# STM32WB35CCU6A register map
File version: 1.0
Registers are 32-bit, access not given, reset 0x0 unless marked. A register's access mark holds for its fields unless they carry their own. Offsets are from the block's base; [hi:lo] are bit positions; {n}, {i} and the like mark numbered series.

## VREFBUF
Base 0x40010030
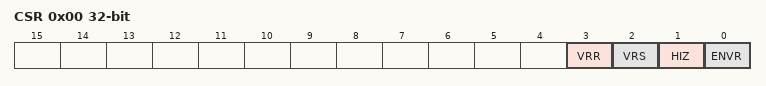
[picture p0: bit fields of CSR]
0x00 CSR
  [3] VRR, [2] VRS, [1] HIZ, [0] ENVR
0x04 CCR
  [5:0] TRIM

## COMP
Base 0x40010200
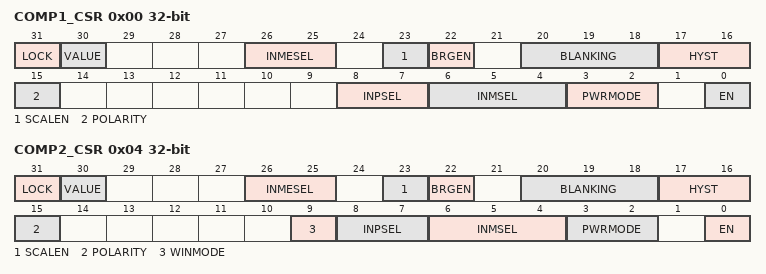
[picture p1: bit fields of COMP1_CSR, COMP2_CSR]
0x00 COMP1_CSR
  [31] LOCK, [30] VALUE, [26:25] INMESEL, [23] SCALEN, [22] BRGEN, [20:18] BLANKING, [17:16] HYST, [15] POLARITY, [8:7] INPSEL, [6:4] INMSEL, [3:2] PWRMODE, [0] EN
0x04 COMP2_CSR
  [31] LOCK, [30] VALUE, [26:25] INMESEL, [23] SCALEN, [22] BRGEN, [20:18] BLANKING, [17:16] HYST, [15] POLARITY, [9] WINMODE, [8:7] INPSEL, [6:4] INMSEL, [3:2] PWRMODE, [0] EN

## TIM1
Base 0x40012C00
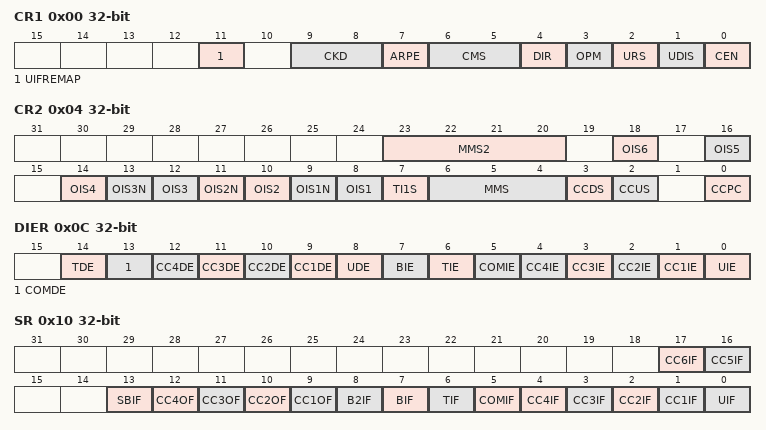
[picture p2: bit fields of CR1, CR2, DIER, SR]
0x00 CR1
  [11] UIFREMAP, [9:8] CKD, [7] ARPE, [6:5] CMS, [4] DIR, [3] OPM, [2] URS, [1] UDIS, [0] CEN
0x04 CR2
  [23:20] MMS2, [2n+6] OIS{n} (n=1..6), [13] OIS3N, [11] OIS2N, [9] OIS1N, [7] TI1S, [6:4] MMS, [3] CCDS, [2] CCUS, [0] CCPC
0x08 SMCR
  [15] ETP, [14] ECE, [13:12] ETPS, [11:8] ETF, [7] MSM, [21:4] TS, [3] OCCS, [16:0] SMS
0x0C DIER
  [14] TDE, [13] COMDE, [n+8] CC{n}DE (n=1..4), [8] UDE, [7] BIE, [6] TIE, [5] COMIE, [n] CC{n}IE (n=1..4), [0] UIE
0x10 SR
  [17] CC6IF, [16] CC5IF, [13] SBIF, [n+8] CC{n}OF (n=1..4), [8] B2IF, [7] BIF, [6] TIF, [5] COMIF, [n] CC{n}IF (n=1..4), [0] UIF
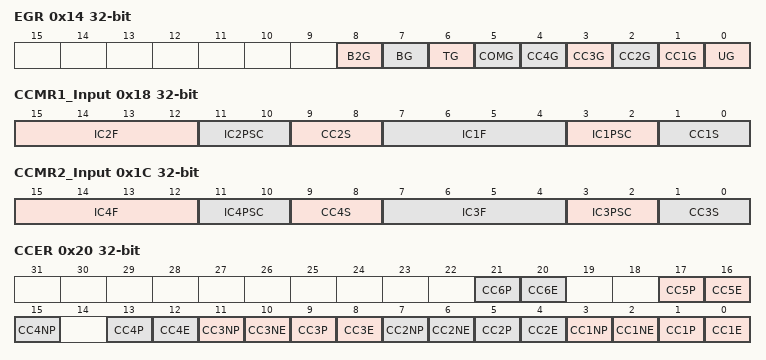
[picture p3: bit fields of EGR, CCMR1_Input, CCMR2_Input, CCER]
0x14 EGR
  [8] B2G, [7] BG, [6] TG, [5] COMG, [n] CC{n}G (n=1..4), [0] UG
0x18 CCMR1_Output
  [15] OC2CE, [24:12] OC2M, [11] OC2PE, [10] OC2FE, [9:8] CC2S, [7] OC1CE, [16:4] OC1M, [3] OC1PE, [2] OC1FE, [1:0] CC1S
0x18 CCMR1_Input
  [15:12] IC2F, [11:10] IC2PSC, [9:8] CC2S, [7:4] IC1F, [3:2] IC1PSC, [1:0] CC1S
0x1C CCMR2_Output
  [15] OC4CE, [24:12] OC4M, [11] OC4PE, [10] OC4FE, [9:8] CC4S, [7] OC3CE, [16:4] OC3M, [3] OC3PE, [2] OC3FE, [1:0] CC3S
0x1C CCMR2_Input
  [15:12] IC4F, [11:10] IC4PSC, [9:8] CC4S, [7:4] IC3F, [3:2] IC3PSC, [1:0] CC3S
0x20 CCER
  [4n-3] CC{n}P (n=1..6), [4n-4] CC{n}E (n=1..6), [4n-1] CC{n}NP (n=1..4), [10] CC3NE, [6] CC2NE, [2] CC1NE
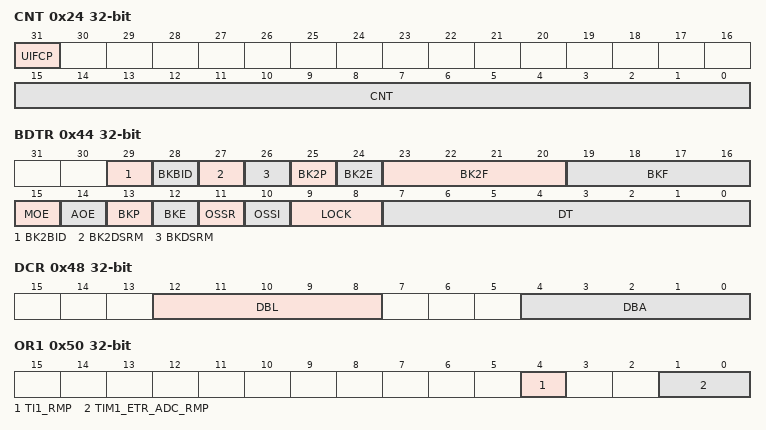
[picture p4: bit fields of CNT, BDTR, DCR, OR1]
0x24 CNT
  [31] UIFCP, [15:0] CNT
0x28 PSC
  [15:0] PSC
0x2C ARR
  [15:0] ARR
0x30 RCR
  [15:0] REP
{0x30+4i} CCR{i} (i=1..4)
  [15:0] CCR{i}
0x44 BDTR
  [29] BK2BID, [28] BKBID, [27] BK2DSRM, [26] BKDSRM, [25] BK2P, [24] BK2E, [23:20] BK2F, [19:16] BKF, [15] MOE, [14] AOE, [13] BKP, [12] BKE, [11] OSSR, [10] OSSI, [9:8] LOCK, [7:0] DT
0x48 DCR
  [12:8] DBL, [4:0] DBA
0x4C DMAR
  [31:0] DMAB
0x50 OR1
  [4] TI1_RMP, [1:0] TIM1_ETR_ADC_RMP
0x54 CCMR3_Output
  [15] OC6CE, [24:12] OC6M, [11] OC6PE, [10] OC6FE, [7] OC5CE, [16:4] OC5M, [3] OC5PE, [2] OC5FE
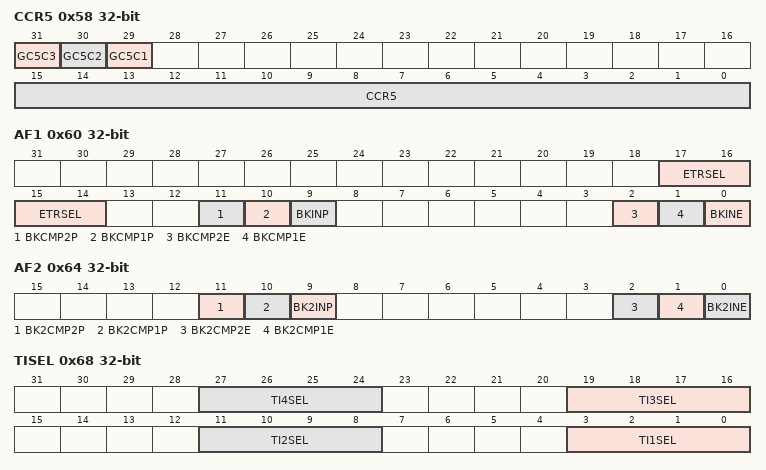
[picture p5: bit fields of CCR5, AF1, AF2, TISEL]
0x58 CCR5
  [31] GC5C3, [30] GC5C2, [29] GC5C1, [15:0] CCR5
0x5C CCR6
  [15:0] CCR6
0x60 AF1
  [17:14] ETRSEL, [11] BKCMP2P, [10] BKCMP1P, [9] BKINP, [2] BKCMP2E, [1] BKCMP1E, [0] BKINE
0x64 AF2
  [11] BK2CMP2P, [10] BK2CMP1P, [9] BK2INP, [2] BK2CMP2E, [1] BK2CMP1E, [0] BK2INE
0x68 TISEL
  [8n-5:8n-8] TI{n}SEL (n=1..4)

## USART1
Base 0x40013800
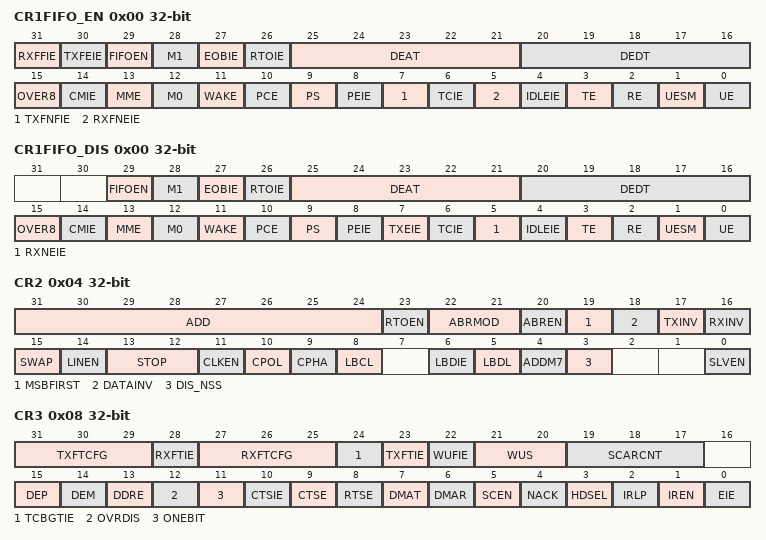
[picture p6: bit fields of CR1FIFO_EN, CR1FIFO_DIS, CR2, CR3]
0x00 CR1FIFO_EN
  [31] RXFFIE, [30] TXFEIE, [29] FIFOEN, [28] M1, [27] EOBIE, [26] RTOIE, [25:21] DEAT, [20:16] DEDT, [15] OVER8, [14] CMIE, [13] MME, [12] M0, [11] WAKE, [10] PCE, [9] PS, [8] PEIE, [7] TXFNFIE, [6] TCIE, [5] RXFNEIE, [4] IDLEIE, [3] TE, [2] RE, [1] UESM, [0] UE
0x00 CR1FIFO_DIS
  [29] FIFOEN, [28] M1, [27] EOBIE, [26] RTOIE, [25:21] DEAT, [20:16] DEDT, [15] OVER8, [14] CMIE, [13] MME, [12] M0, [11] WAKE, [10] PCE, [9] PS, [8] PEIE, [7] TXEIE, [6] TCIE, [5] RXNEIE, [4] IDLEIE, [3] TE, [2] RE, [1] UESM, [0] UE
0x04 CR2
  [31:24] ADD, [23] RTOEN, [22:21] ABRMOD, [20] ABREN, [19] MSBFIRST, [18] DATAINV, [17] TXINV, [16] RXINV, [15] SWAP, [14] LINEN, [13:12] STOP, [11] CLKEN, [10] CPOL, [9] CPHA, [8] LBCL, [6] LBDIE, [5] LBDL, [4] ADDM7, [3] DIS_NSS, [0] SLVEN
0x08 CR3
  [31:29] TXFTCFG, [28] RXFTIE, [27:25] RXFTCFG, [24] TCBGTIE, [23] TXFTIE, [22] WUFIE, [21:20] WUS, [19:17] SCARCNT, [15] DEP, [14] DEM, [13] DDRE, [12] OVRDIS, [11] ONEBIT, [10] CTSIE, [9] CTSE, [8] RTSE, [7] DMAT, [6] DMAR, [5] SCEN, [4] NACK, [3] HDSEL, [2] IRLP, [1] IREN, [0] EIE
0x0C BRR
  [15:0] BRR
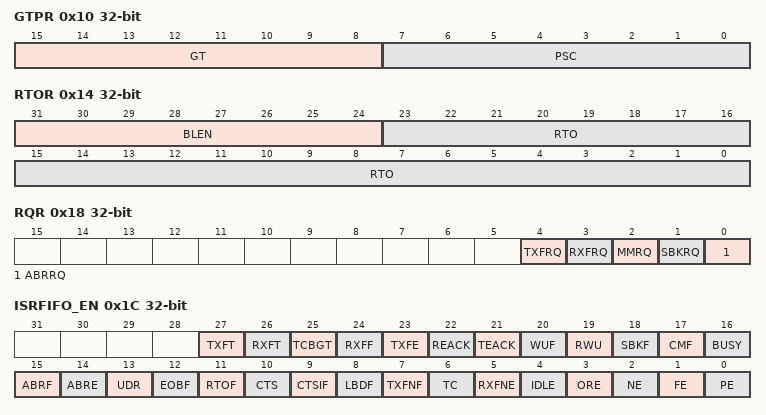
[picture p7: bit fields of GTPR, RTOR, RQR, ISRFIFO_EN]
0x10 GTPR
  [15:8] GT, [7:0] PSC
0x14 RTOR
  [31:24] BLEN, [23:0] RTO
0x18 RQR
  [4] TXFRQ, [3] RXFRQ, [2] MMRQ, [1] SBKRQ, [0] ABRRQ
0x1C ISRFIFO_EN
  [27] TXFT, [26] RXFT, [25] TCBGT, [24] RXFF, [23] TXFE, [22] REACK, [21] TEACK, [20] WUF, [19] RWU, [18] SBKF, [17] CMF, [16] BUSY, [15] ABRF, [14] ABRE, [13] UDR, [12] EOBF, [11] RTOF, [10] CTS, [9] CTSIF, [8] LBDF, [7] TXFNF, [6] TC, [5] RXFNE, [4] IDLE, [3] ORE, [2] NE, [1] FE, [0] PE
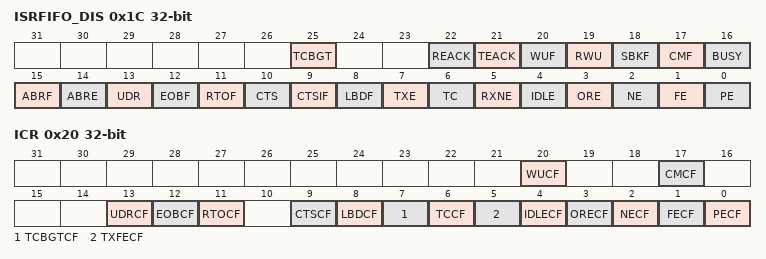
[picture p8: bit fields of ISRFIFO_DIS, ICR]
0x1C ISRFIFO_DIS
  [25] TCBGT, [22] REACK, [21] TEACK, [20] WUF, [19] RWU, [18] SBKF, [17] CMF, [16] BUSY, [15] ABRF, [14] ABRE, [13] UDR, [12] EOBF, [11] RTOF, [10] CTS, [9] CTSIF, [8] LBDF, [7] TXE, [6] TC, [5] RXNE, [4] IDLE, [3] ORE, [2] NE, [1] FE, [0] PE
0x20 ICR
  [20] WUCF, [17] CMCF, [13] UDRCF, [12] EOBCF, [11] RTOCF, [9] CTSCF, [8] LBDCF, [7] TCBGTCF, [6] TCCF, [5] TXFECF, [4] IDLECF, [3] ORECF, [2] NECF, [1] FECF, [0] PECF
0x24 RDR
  [8:0] RDR
0x28 TDR
  [8:0] TDR
0x2C PRESC
  [3:0] PRESCALER
